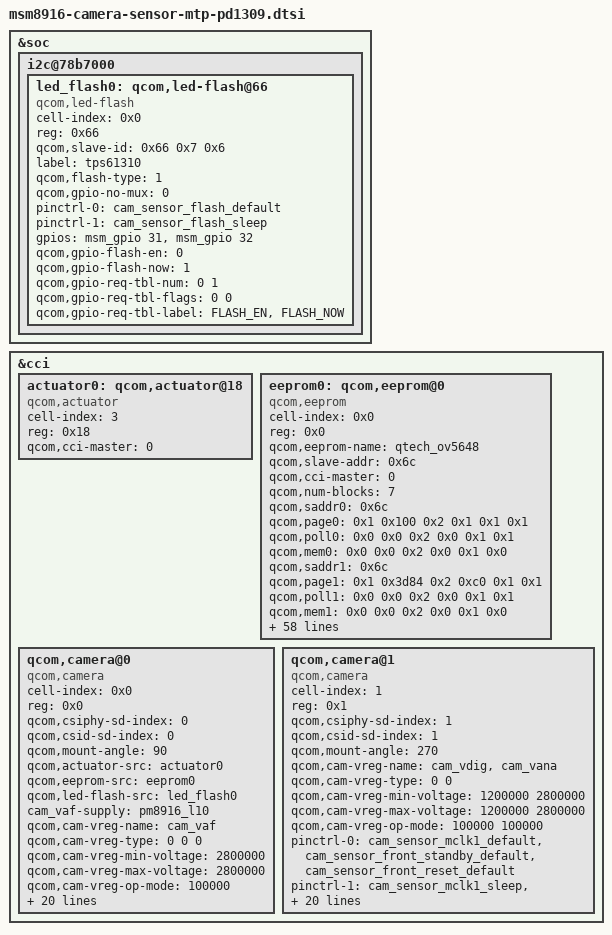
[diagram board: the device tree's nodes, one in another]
/* Copyright (c) 2020, The Linux Foundation. All rights reserved.
*  Copyright (c) 2020, the_shahnawaz_sheikh (sheikhshahnawaz41299).
*
* This program is free software; you can redistribute it and/or modify
* it under the terms of the GNU General Public License version 2 and
* only version 2 as published by the Free Software Foundation.
*
* This program is distributed in the hope that it will be useful,
* but WITHOUT ANY WARRANTY; without even the implied warranty of
* MERCHANTABILITY or FITNESS FOR A PARTICULAR PURPOSE.  See the
* GNU General Public License for more details.
*/
&soc {
     i2c@78b7000 {
          led_flash0: qcom,led-flash@66 {
				cell-index = <0x0>;
				reg = <0x66>;
				qcom,slave-id = <0x66 0x7 0x6>;
				compatible = "qcom,led-flash";
				label = "tps61310";
				qcom,flash-type = <1>;
				qcom,gpio-no-mux = <0>;
				pinctrl-names = "cam_flash_default", "cam_flash_suspend";
				pinctrl-0 = <&cam_sensor_flash_default>;
				pinctrl-1 = <&cam_sensor_flash_sleep>;
				gpios = <&msm_gpio 31 0>, <&msm_gpio 32 0>;
				qcom,gpio-flash-en = <0>;
				qcom,gpio-flash-now = <1>;
				qcom,gpio-req-tbl-num = <0 1>;
				qcom,gpio-req-tbl-flags = <0 0>;
				qcom,gpio-req-tbl-label = "FLASH_EN", "FLASH_NOW";
			};
		};
     
};

&cci {
	/delete-node/ qcom,actuator@0;
	/delete-node/ qcom,led-flash@0;

	actuator0: qcom,actuator@18 {
				cell-index = <3>;
				reg = <0x18>;
				compatible = "qcom,actuator";
				qcom,cci-master = <0>;
    };

	/delete-node/ qcom,eeprom@20;
	/delete-node/ qcom,eeprom@1;

	eeprom0: qcom,eeprom@0 {
				cell-index = <0x0>;
				reg = <0x0>;
				qcom,eeprom-name = "qtech_ov5648";
				compatible = "qcom,eeprom";
				qcom,slave-addr = <0x6c>;
				qcom,cci-master = <0>;
                
				qcom,num-blocks = <7>;
				
				qcom,saddr0 = <0x6c>;
				qcom,page0 = <0x1 0x100 0x2 0x1 0x1 0x1>;
				qcom,poll0 = <0x0 0x0 0x2 0x0 0x1 0x1>;
				qcom,mem0 = <0x0 0x0 0x2 0x0 0x1 0x0>;
				
				qcom,saddr1 = <0x6c>;
				qcom,page1 = <0x1 0x3d84 0x2 0xc0 0x1 0x1>;
				qcom,poll1 = <0x0 0x0 0x2 0x0 0x1 0x1>;
				qcom,mem1 = <0x0 0x0 0x2 0x0 0x1 0x0>;
				
				qcom,saddr2 = <0x6c>;
				qcom,page2 = <0x1 0x3d85 0x2 0x0 0x1 0x1>;
				qcom,poll2 = <0x0 0x0 0x2 0x0 0x1 0x1>;
				qcom,mem2 = <0x0 0x0 0x2 0x0 0x1 0x0>;
				
				qcom,saddr3 = <0x6c>;
				qcom,page3 = <0x1 0x3d86 0x2 0xf 0x1 0x1>;
				qcom,pageen3 = <0x1 0x3d81 0x2 0x1 0x1 0xa>;
				qcom,poll3 = <0x0 0x0 0x2 0x0 0x1 0x1>;
				qcom,mem3 = <0x10 0x3d00 0x2 0x0 0x1 0x0>;
				
				qcom,saddr4 = <0x6c>;
				qcom,page4 = <0x1 0x3d84 0x2 0xc0 0x1 0x1>;
				qcom,poll4 = <0x0 0x0 0x2 0x0 0x1 0x1>;
				qcom,mem4 = <0x0 0x0 0x2 0x0 0x1 0x0>;
				
				qcom,saddr5 = <0x6c>;
				qcom,page5 = <0x1 0x3d85 0x2 0x10 0x1 0x1>;
				qcom,poll5 = <0x0 0x0 0x2 0x0 0x1 0x1>;
				qcom,mem5 = <0x0 0x0 0x2 0x0 0x1 0x0>;
				
				qcom,saddr6 = <0x6c>;
				qcom,page6 = <0x1 0x3d86 0x2 0x1f 0x1 0x1>;
				qcom,pageen6 = <0x1 0x3d81 0x2 0x1 0x1 0xa>;
				qcom,poll6 = <0x0 0x0 0x2 0x0 0x1 0x1>;
				qcom,mem6 = <0x10 0x3d00 0x2 0x0 0x1 0x0>;
				
				qcom,cam-vreg-name = "cam_vana", "cam_vdig", "cam_vio", "cam_vaf";
				qcom,cam-vreg-type = <0x0 0x0 0x0 0x0>;
				qcom,cam-vreg-min-voltage = <2850000 1200000 1800000 280000>;
				qcom,cam-vreg-max-voltage = <2850000 1200000 1800000 280000>;
				qcom,cam-vreg-op-mode = <100000 100000 100000 100000>;
				
				pinctrl-names = "cam_default", "cam_suspend";
				pinctrl-0 = <&cam_sensor_mclk0_default     &cam_sensor_rear_default>;
				pinctrl-1 = <&cam_sensor_mclk0_sleep &cam_sensor_rear_sleep>;
				
				gpios = <&msm_gpio 26 0>,
                        <&msm_gpio 35 0>,
                        <&msm_gpio 52 0>,
                        <&msm_gpio 16 0>,
                        <&msm_gpio 34 0>;
                        
				qcom,gpio-reset = <1>;
				qcom,gpio-vana = <2>;
				qcom,gpio-vio = <3>;
				qcom,gpio-standby = <4>;
				qcom,gpio-req-tbl-num = <0 1 2 3 4>;
				qcom,gpio-req-tbl-flags = <1 0 0 0 0>;
				qcom,csi-lane-assign = <0x4320>;
				qcom,csi-lane-mask = <0x1f>;
				qcom,gpio-req-tbl-label = "CAMIF_MCLK", "CAM_RESET1", "CAM_VANA", "CAM_VIO", "CAM_STANDBY";
				qcom,cam-power-seq-type = "sensor_gpio", "sensor_gpio", "sensor_clk", "sensor_gpio", "sensor_gpio";
				qcom,cam-power-seq-val = "sensor_gpio_vio", "sensor_gpio_vana", "sensor_cam_mclk", "sensor_gpio_standby", "sensor_gpio_reset";
				qcom,cam-power-seq-cfg-val = <1 1 23880000 1 1>;
				qcom,cam-power-seq-delay = <1 1 5 5 10>;
				qcom,mclk-23880000;
				clocks = <&clock_gcc clk_mclk0_clk_src>,
				           <&clock_gcc clk_gcc_camss_mclk0_clk>;
				clock-names = "cam_src_clk", "cam_clk";
			};

	/delete-node/ qcom,camera@78;
	/delete-node/ qcom,camera@0;
	/delete-node/ qcom,camera@1;

	 qcom,camera@0 {
				cell-index = <0x0>;
				compatible = "qcom,camera";
				reg = <0x0>;
				qcom,csiphy-sd-index = <0>;
				qcom,csid-sd-index = <0>;
				qcom,mount-angle = <90>;
				qcom,actuator-src = <&actuator0>;
				qcom,eeprom-src = <&eeprom0>;
				qcom,led-flash-src = <&led_flash0>;
				cam_vaf-supply = <&pm8916_l10>;
				qcom,cam-vreg-name = "cam_vaf";
				qcom,cam-vreg-type = <0 0 0>;
				qcom,cam-vreg-min-voltage = <2800000>;
				qcom,cam-vreg-max-voltage = <2800000>;
				qcom,cam-vreg-op-mode = <100000>;
				pinctrl-names = "cam_default", "cam_suspend";
				pinctrl-0 = <&cam_sensor_mclk0_default
				                &cam_sensor_rear_default>;
				pinctrl-1 = <&cam_sensor_mclk0_sleep                                 &cam_sensor_rear_sleep>;
				gpios = <&msm_gpio 26 0>,
                        <&msm_gpio 35 0>,
                        <&msm_gpio 34 0>,
                        <&msm_gpio 52 0>,
                        <&msm_gpio 16 0>;
				qcom,gpio-reset = <1>;
				qcom,gpio-standby = <2>;
				qcom,gpio-vana = <3>;
				qcom,gpio-vio = <4>;
				qcom,gpio-req-tbl-num = <0 1 2 3 4>;
				qcom,gpio-req-tbl-flags = <1 0 0 0 0>;
				qcom,gpio-req-tbl-label = "CAMIF_MCLK", "CAM_RESET1", "CAM_STANDBY", "CAM_VANA", "CAM_VIO";
				qcom,sensor-position = <0>;
				qcom,sensor-mode = <0>;
				qcom,cci-master = <0>;
				qcom,mclk-23880000;
				status = "ok";
				clocks = <&clock_gcc clk_mclk0_clk_src>,
				            <&clock_gcc clk_gcc_camss_mclk0_clk>;
				clock-names = "cam_src_clk", "cam_clk";
			};

			qcom,camera@1 {
				cell-index = <1>;
				compatible = "qcom,camera";
				reg = <0x1>;
				qcom,csiphy-sd-index = <1>;
				qcom,csid-sd-index = <1>;
				qcom,mount-angle = <270>;
				qcom,cam-vreg-name = "cam_vdig", "cam_vana";
				qcom,cam-vreg-type = <0 0>;
				qcom,cam-vreg-min-voltage = <1200000 2800000>;
				qcom,cam-vreg-max-voltage = <1200000 2800000>;
				qcom,cam-vreg-op-mode = <100000 100000>;
				pinctrl-names = "cam_default", "cam_suspend";
				pinctrl-0 = <&cam_sensor_mclk1_default &cam_sensor_front_standby_default &cam_sensor_front_reset_default>;
				pinctrl-1 = <&cam_sensor_mclk1_sleep &cam_sensor_front_standby_sleep &cam_sensor_front_reset_sleep>;
				gpios = <&msm_gpio 27 0>,
                        <&msm_gpio 28 0>,
                        <&msm_gpio 33 0>,
                        <&msm_gpio 52 0>,
                        <&msm_gpio 16 0>,
                        <&msm_gpio 16 0>;
				qcom,gpio-reset = <1>;
				qcom,gpio-standby = <2>;
				qcom,gpio-vana = <3>;
				qcom,gpio-vdig = <4>;
				qcom,gpio-vio = <5>;
				qcom,gpio-req-tbl-num = <0 1 2 3 4 5>;
				qcom,gpio-req-tbl-flags = <1 0 0 0 0 0>;
				qcom,gpio-req-tbl-label = "CAMIF_MCLK", "CAM_RESET", "CAM_STANDBY", "CAM_VANA1", "CAM_VDIG1", "CAM_VIO";
				qcom,sensor-position = <1>;
				qcom,sensor-mode = <0>;
				qcom,cci-master = <0>;
				qcom,mclk-23880000;
				status = "ok";
				clocks = <&clock_gcc clk_mclk1_clk_src>,
				<&clock_gcc clk_gcc_camss_mclk1_clk>;
				clock-names = "cam_src_clk", "cam_clk";
			};
};
